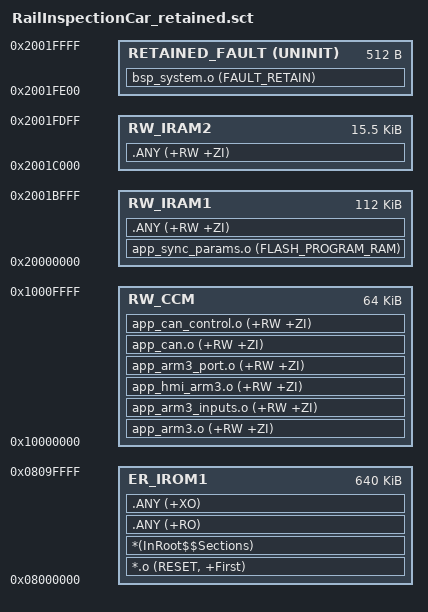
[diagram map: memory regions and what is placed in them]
; Versioned SRAM layout: final 512 bytes survive warm resets.
LR_IROM1 0x08000000 0x000A0000 {
  ER_IROM1 0x08000000 0x000A0000 {
    *.o (RESET, +First)
    *(InRoot$$Sections)
    .ANY (+RO)
    .ANY (+XO)
  }
  ; CCM is CPU-only: no DMA/USB/USART peripheral buffers may be placed here.
  RW_CCM 0x10000000 0x00010000 {
    app_arm3.o (+RW +ZI)
    app_arm3_inputs.o (+RW +ZI)
    app_hmi_arm3.o (+RW +ZI)
    app_arm3_port.o (+RW +ZI)
    app_can.o (+RW +ZI)
    app_can_control.o (+RW +ZI)
  }
  RW_IRAM1 0x20000000 0x0001C000 {
    app_sync_params.o (FLASH_PROGRAM_RAM)
    .ANY (+RW +ZI)
  }
  RW_IRAM2 0x2001C000 0x00003E00 { .ANY (+RW +ZI) }
  RETAINED_FAULT 0x2001FE00 UNINIT 0x00000200 {
    bsp_system.o (FAULT_RETAIN)
  }
}
